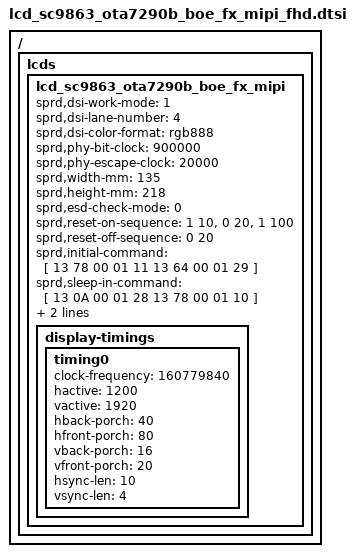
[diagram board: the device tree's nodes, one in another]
/ { lcds {
	lcd_sc9863_ota7290b_boe_fx_mipi: lcd_sc9863_ota7290b_boe_fx_mipi {

		sprd,dsi-work-mode = <1>;
		sprd,dsi-lane-number = <4>;
		sprd,dsi-color-format = "rgb888";

		sprd,phy-bit-clock = <900000>;
		sprd,phy-escape-clock = <20000>;

		sprd,width-mm = <135>;
		sprd,height-mm = <218>;

		sprd,esd-check-mode = <0>;

		sprd,reset-on-sequence = <1 10>, <0 20>, <1 100>;
		sprd,reset-off-sequence = <0 20>;


		sprd,initial-command = [
			13 78 00 01 11
			13 64 00 01 29
			];
		sprd,sleep-in-command = [
			13 0A 00 01 28
			13 78 00 01 10
			];
		sprd,sleep-out-command = [
			13 78 00 01 11
			13 64 00 01 29
			];

		display-timings {
			timing0 {
			clock-frequency = <160779840>;
			hactive = <1200>;
			vactive = <1920>;
			hback-porch = <40>;
			hfront-porch = <80>;
			vback-porch = <16>;
			vfront-porch = <20>;
			hsync-len = <10>;
			vsync-len = <4>;
			};
		};
	};
};};

